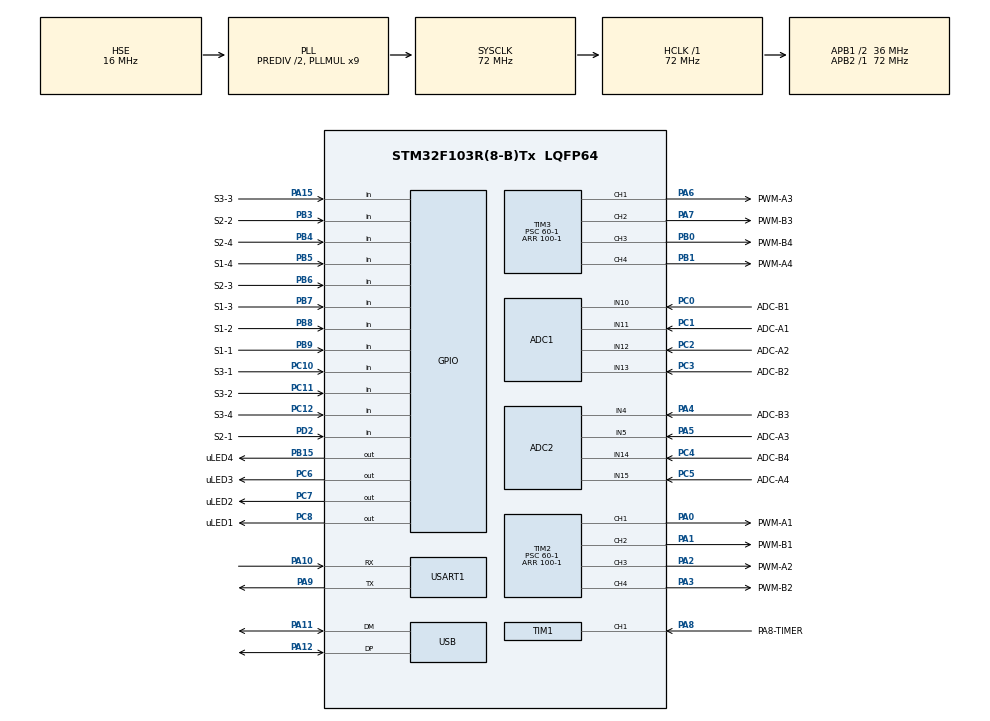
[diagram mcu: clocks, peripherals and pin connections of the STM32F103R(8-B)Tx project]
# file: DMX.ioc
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PC10.GPIO_PuPd=GPIO_PULLDOWN
PC12.Signal=GPIO_Input
PB14.GPIO_Label=PB14-TIMER
PC6.GPIO_Label=uLED3
PA6.GPIO_Label=PWM-A3
PB6.GPIO_Label=S2-3
TIM3.Channel-PWM\ Generation4\ CH4=TIM_CHANNEL_4
RCC.SYSCLKSource=RCC_SYSCLKSOURCE_PLLCLK
RCC.APB2TimFreq_Value=72000000
PB6.Signal=GPIO_Input
PC7.Signal=GPIO_Output
PC3.Signal=ADCx_IN13
SH.ADCx_IN15.0=ADC2_IN15,IN15
PC4.GPIO_Label=ADC-B4
PB1.GPIO_Label=PWM-A4
PA8.Signal=S_TIM1_CH1
TIM1.Channel-Input_Capture2_from_TI1=TIM_CHANNEL_2
VP_TIM1_VS_ClockSourceINT.Mode=Internal
Mcu.Package=LQFP64
PB9.Signal=GPIO_Input
TIM2.Prescaler=60-1
PB1.Signal=S_TIM3_CH4
SH.ADCx_IN14.0=ADC2_IN14,IN14
PA10.Signal=USART1_RX
PB9.GPIO_PuPd=GPIO_PULLDOWN
RCC.APB1TimFreq_Value=72000000
TIM1.Period=100-1
PC12.GPIO_PuPd=GPIO_PULLDOWN
PA4.GPIO_Label=ADC-B3
PB7.GPIO_PuPd=GPIO_PULLDOWN
PD2.GPIO_PuPd=GPIO_PULLDOWN
PB6.GPIO_PuPd=GPIO_PULLDOWN
PB8.GPIO_PuPd=GPIO_PULLDOWN
PC2.Signal=ADCx_IN12
PC6.Signal=GPIO_Output
RCC.USBPrescaler=RCC_USBCLKSOURCE_PLL_DIV1_5
PC0.Signal=ADCx_IN10
RCC.APB1CLKDivider=RCC_HCLK_DIV2
PA0-WKUP.GPIO_Label=PWM-A1
PA0-WKUP.Signal=S_TIM2_CH1_ETR
TIM3.Channel-PWM\ Generation3\ CH3=TIM_CHANNEL_3
PB8.GPIO_Label=S1-2
PA8.GPIO_Label=PA8-TIMER
PA9.Signal=USART1_TX
PB4.GPIO_PuPd=GPIO_PULLDOWN
PC6.PinState=GPIO_PIN_SET
PB14.Signal=TIM1_CH2N
PA5.Signal=ADCx_IN5
PB4.GPIO_Label=S2-4
PB15.GPIO_Label=uLED4
PA1.GPIO_Label=PWM-B1
SH.ADCx_IN4.0=ADC2_IN4,IN4
TIM2.Period=100-1
PA13.Mode=Serial_Wire
PC7.GPIO_Label=uLED2
ADC1.SamplingTime-1\#ChannelRegularConversion=ADC_SAMPLETIME_1CYCLE_5
PA4.Signal=ADCx_IN4
PB5.Signal=GPIO_Input
ADC1.master=1
PA5.GPIO_Label=ADC-A3
ADC2.NbrOfConversionFlag=1
TIM1.Channel-Input_Capture1_from_TI1=TIM_CHANNEL_1
PB5.GPIO_PuPd=GPIO_PULLDOWN
RCC.HSEDivPLL=RCC_HSE_PREDIV_DIV2
PC12.GPIO_Label=S3-4
USART1.VirtualMode=VM_ASYNC
ADC1.Rank-1\#ChannelRegularConversion=1
PA11.Signal=USB_DM
SH.S_TIM2_CH1_ETR.0=TIM2_CH1,PWM Generation1 CH1
ProjectManager.HeapSize=0x200
SH.ADCx_IN5.0=ADC2_IN5,IN5
NVIC.PriorityGroup=NVIC_PRIORITYGROUP_4
TIM3.Channel-PWM\ Generation2\ CH2=TIM_CHANNEL_2
PC3.GPIO_Label=ADC-B2
PD2.Signal=GPIO_Input
PB0.Signal=S_TIM3_CH3
PC1.Signal=ADCx_IN11
PD2.GPIO_Label=S2-1
Mcu.Family=STM32F1
USB_DEVICE.CLASS_NAME_FS=CDC
ADC2.Channel-0\#ChannelRegularConversion=ADC_CHANNEL_4
PC10.Signal=GPIO_Input
PC0.GPIO_Label=ADC-B1
PA11.Mode=Device
PB0.GPIO_Label=PWM-B4
TIM2.Channel-PWM\ Generation2\ CH2=TIM_CHANNEL_2
PB15.Signal=GPIO_Output
PB15.PinState=GPIO_PIN_SET
ProjectManager.StackSize=0x400
PC8.PinState=GPIO_PIN_SET
PD1-OSC_OUT.Signal=RCC_OSC_OUT
PA15.GPIO_Label=S3-3
PC11.GPIO_PuPd=GPIO_PULLDOWN
PA12.Signal=USB_DP
TIM1.Prescaler=60-1
RCC.HCLKFreq_Value=72000000
TIM3.Period=100-1
RCC.AHBFreq_Value=72000000
TIM3.Channel-PWM\ Generation1\ CH1=TIM_CHANNEL_1
RCC.HSE_VALUE=16000000
RCC.PLLMUL=RCC_PLL_MUL9
PB3.GPIO_PuPd=GPIO_PULLDOWN
PA14.Mode=Serial_Wire
TIM3.Prescaler=60-1
PC11.GPIO_Label=S3-2
PC7.PinState=GPIO_PIN_SET
PB7.Signal=GPIO_Input
TIM2.Channel-PWM\ Generation1\ CH1=TIM_CHANNEL_1
SH.S_TIM3_CH1.0=TIM3_CH1,PWM Generation1 CH1
PB7.GPIO_Label=S1-3
PA6.Signal=S_TIM3_CH1
PA2.GPIO_Label=PWM-A2
PC8.GPIO_ModeDefaultOutputPP=GPIO_MODE_OUTPUT_PP
PA15.Signal=GPIO_Input
ADC2.SamplingTime-0\#ChannelRegularConversion=ADC_SAMPLETIME_1CYCLE_5
PB5.GPIO_Label=S1-4
PC5.Signal=ADCx_IN15
ADC2.Rank-0\#ChannelRegularConversion=1
PC2.GPIO_Label=ADC-A2
VP_TIM3_VS_ClockSourceINT.Mode=Internal
PB4.Signal=GPIO_Input
PA3.Signal=S_TIM2_CH4
PB3.GPIO_Label=S2-2
TIM2.Channel-PWM\ Generation4\ CH4=TIM_CHANNEL_4
SH.ADCx_IN13.0=ADC1_IN13,IN13
PD1-OSC_OUT.Mode=HSE-External-Oscillator
PB9.GPIO_Label=S1-1
PC10.GPIO_Label=S3-1
PA10.Mode=Asynchronous
USB_DEVICE.VirtualModeFS=Cdc_FS
PC11.Signal=GPIO_Input
PC8.Signal=GPIO_Output
PC4.Signal=ADCx_IN14
PD0-OSC_IN.Signal=RCC_OSC_IN
SH.S_TIM3_CH3.0=TIM3_CH3,PWM Generation3 CH3
RCC.ADCPresc=RCC_ADCPCLK2_DIV6
PC8.GPIO_Label=uLED1
PA13.Signal=SYS_JTMS-SWDIO
SH.S_TIM2_CH2.0=TIM2_CH2,PWM Generation2 CH2
PA9.Mode=Asynchronous
SH.ADCx_IN12.0=ADC1_IN12,IN12
SH.S_TIM1_CH1.0=TIM1_CH1,Input_Capture1_from_TI1
SH.S_TIM1_CH1.1=TIM1_CH1,Input_Capture2_from_TI1
ProjectManager.TargetToolchain=STM32CubeIDE
VP_USB_DEVICE_VS_USB_DEVICE_CDC_FS.Mode=CDC_FS
ADC1.Channel-1\#ChannelRegularConversion=ADC_CHANNEL_10
RCC.USBFreq_Value=48000000
PA1.Signal=S_TIM2_CH2
PD0-OSC_IN.Mode=HSE-External-Oscillator
SH.S_TIM3_CH2.0=TIM3_CH2,PWM Generation2 CH2
board=custom
RCC.APB2Freq_Value=72000000
SH.ADCx_IN11.0=ADC1_IN11,IN11
VP_TIM2_VS_ClockSourceINT.Mode=Internal
SH.S_TIM2_CH3.0=TIM2_CH3,PWM Generation3 CH3
NVIC.USB_LP_CAN1_RX0_IRQn=true\:0\:0\:false\:false\:true\:false\:true
PC1.GPIO_Label=ADC-A1
TIM2.Channel-PWM\ Generation3\ CH3=TIM_CHANNEL_3
Mcu.Name=STM32F103R(8-B)Tx
PA2.Signal=S_TIM2_CH3
PB3.Signal=GPIO_Input
RCC.SYSCLKFreq_VALUE=72000000
PA7.GPIO_Label=PWM-B3
PA12.Mode=Device
PC5.GPIO_Label=ADC-A4
PA14.Signal=SYS_JTCK-SWCLK
SH.ADCx_IN10.0=ADC1_IN10,IN10
SH.S_TIM2_CH4.0=TIM2_CH4,PWM Generation4 CH4
ADC1.NbrOfConversionFlag=1
PA15.GPIO_PuPd=GPIO_PULLDOWN
PB8.Signal=GPIO_Input
RCC.APB1Freq_Value=36000000
USB_DEVICE.VirtualMode=Cdc
PA3.GPIO_Label=PWM-B2
SH.S_TIM3_CH4.0=TIM3_CH4,PWM Generation4 CH4
PA7.Signal=S_TIM3_CH2

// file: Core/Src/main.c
/* USER CODE BEGIN Header */
/**
  ******************************************************************************
  * @file           : main.c
  * @brief          : Main program body
  ******************************************************************************
  * @attention
  *
  * <h2><center>&copy; Copyright (c) 2021 STMicroelectronics.
  * All rights reserved.</center></h2>
  *
  * This software component is licensed by ST under BSD 3-Clause license,
  * the "License"; You may not use this file except in compliance with the
  * License. You may obtain a copy of the License at:
  *                        opensource.org/licenses/BSD-3-Clause
  *
  ******************************************************************************
  */
/* USER CODE END Header */
#include "main.h"
#include "usb_device.h"

/* USER CODE BEGIN Includes */

#include "core.h"

/* USER CODE END Includes */

ADC_HandleTypeDef hadc1;
ADC_HandleTypeDef hadc2;

TIM_HandleTypeDef htim1;
TIM_HandleTypeDef htim2;
TIM_HandleTypeDef htim3;

UART_HandleTypeDef huart1;

void SystemClock_Config(void);
static void MX_GPIO_Init(void);
static void MX_ADC1_Init(void);
static void MX_ADC2_Init(void);
static void MX_TIM1_Init(void);
static void MX_TIM2_Init(void);
static void MX_TIM3_Init(void);
static void MX_USART1_UART_Init(void);

/* USER CODE BEGIN 0 */

void TogglePortWithDelay(GPIO_TypeDef *GPIOx, uint16_t GPIO_Pin, uint8_t delay)
{
	HAL_GPIO_TogglePin(GPIOx, GPIO_Pin);
	HAL_Delay(delay);
}

/* USER CODE END 0 */

int main(void)
{

  /* MCU Configuration--------------------------------------------------------*/

  /* Reset of all peripherals, Initializes the Flash interface and the Systick. */
  HAL_Init();

  /* Configure the system clock */
  SystemClock_Config();

  /* Initialize all configured peripherals */
  MX_GPIO_Init();
  MX_ADC1_Init();
  MX_ADC2_Init();
  MX_TIM1_Init();
  MX_TIM2_Init();
  MX_TIM3_Init();
  MX_USART1_UART_Init();
  MX_USB_DEVICE_Init();
  /* USER CODE BEGIN 2 */

  if (!core_init())
    Error_Handler();

  /* USER CODE END 2 */

  /* Infinite loop */
  while (1)
  {

    /* USER CODE BEGIN 3 */

	  core_process();

  }
  /* USER CODE END 3 */
}

void SystemClock_Config(void)
{
  RCC_OscInitTypeDef RCC_OscInitStruct = {0};
  RCC_ClkInitTypeDef RCC_ClkInitStruct = {0};
  RCC_PeriphCLKInitTypeDef PeriphClkInit = {0};

  /** Initializes the RCC Oscillators according to the specified parameters
  * in the RCC_OscInitTypeDef structure.
  */
  RCC_OscInitStruct.OscillatorType = RCC_OSCILLATORTYPE_HSE;
  RCC_OscInitStruct.HSEState = RCC_HSE_ON;
  RCC_OscInitStruct.HSEPredivValue = RCC_HSE_PREDIV_DIV2;
  RCC_OscInitStruct.HSIState = RCC_HSI_ON;
  RCC_OscInitStruct.PLL.PLLState = RCC_PLL_ON;
  RCC_OscInitStruct.PLL.PLLSource = RCC_PLLSOURCE_HSE;
  RCC_OscInitStruct.PLL.PLLMUL = RCC_PLL_MUL9;
  if (HAL_RCC_OscConfig(&RCC_OscInitStruct) != HAL_OK)
  {
    Error_Handler();
  }
  /** Initializes the CPU, AHB and APB buses clocks
  */
  RCC_ClkInitStruct.ClockType = RCC_CLOCKTYPE_HCLK|RCC_CLOCKTYPE_SYSCLK
                              |RCC_CLOCKTYPE_PCLK1|RCC_CLOCKTYPE_PCLK2;
  RCC_ClkInitStruct.SYSCLKSource = RCC_SYSCLKSOURCE_PLLCLK;
  RCC_ClkInitStruct.AHBCLKDivider = RCC_SYSCLK_DIV1;
  RCC_ClkInitStruct.APB1CLKDivider = RCC_HCLK_DIV2;
  RCC_ClkInitStruct.APB2CLKDivider = RCC_HCLK_DIV1;

  if (HAL_RCC_ClockConfig(&RCC_ClkInitStruct, FLASH_LATENCY_2) != HAL_OK)
  {
    Error_Handler();
  }
  PeriphClkInit.PeriphClockSelection = RCC_PERIPHCLK_ADC|RCC_PERIPHCLK_USB;
  PeriphClkInit.AdcClockSelection = RCC_ADCPCLK2_DIV6;
  PeriphClkInit.UsbClockSelection = RCC_USBCLKSOURCE_PLL_DIV1_5;
  if (HAL_RCCEx_PeriphCLKConfig(&PeriphClkInit) != HAL_OK)
  {
    Error_Handler();
  }
}

static void MX_ADC1_Init(void)
{

  ADC_ChannelConfTypeDef sConfig = {0};

  /** Common config
  */
  hadc1.Instance = ADC1;
  hadc1.Init.ScanConvMode = ADC_SCAN_DISABLE;
  hadc1.Init.ContinuousConvMode = DISABLE;
  hadc1.Init.DiscontinuousConvMode = DISABLE;
  hadc1.Init.ExternalTrigConv = ADC_SOFTWARE_START;
  hadc1.Init.DataAlign = ADC_DATAALIGN_RIGHT;
  hadc1.Init.NbrOfConversion = 1;
  if (HAL_ADC_Init(&hadc1) != HAL_OK)
  {
    Error_Handler();
  }
  /** Configure Regular Channel
  */
  sConfig.Channel = ADC_CHANNEL_10;
  sConfig.Rank = ADC_REGULAR_RANK_1;
  sConfig.SamplingTime = ADC_SAMPLETIME_1CYCLE_5;
  if (HAL_ADC_ConfigChannel(&hadc1, &sConfig) != HAL_OK)
  {
    Error_Handler();
  }

}

static void MX_ADC2_Init(void)
{

  ADC_ChannelConfTypeDef sConfig = {0};

  /** Common config
  */
  hadc2.Instance = ADC2;
  hadc2.Init.ScanConvMode = ADC_SCAN_DISABLE;
  hadc2.Init.ContinuousConvMode = DISABLE;
  hadc2.Init.DiscontinuousConvMode = DISABLE;
  hadc2.Init.ExternalTrigConv = ADC_SOFTWARE_START;
  hadc2.Init.DataAlign = ADC_DATAALIGN_RIGHT;
  hadc2.Init.NbrOfConversion = 1;
  if (HAL_ADC_Init(&hadc2) != HAL_OK)
  {
    Error_Handler();
  }
  /** Configure Regular Channel
  */
  sConfig.Channel = ADC_CHANNEL_4;
  sConfig.Rank = ADC_REGULAR_RANK_1;
  sConfig.SamplingTime = ADC_SAMPLETIME_1CYCLE_5;
  if (HAL_ADC_ConfigChannel(&hadc2, &sConfig) != HAL_OK)
  {
    Error_Handler();
  }

}

static void MX_TIM1_Init(void)
{

  TIM_ClockConfigTypeDef sClockSourceConfig = {0};
  TIM_MasterConfigTypeDef sMasterConfig = {0};
  TIM_IC_InitTypeDef sConfigIC = {0};

  htim1.Instance = TIM1;
  htim1.Init.Prescaler = 60-1;
  htim1.Init.CounterMode = TIM_COUNTERMODE_UP;
  htim1.Init.Period = 100-1;
  htim1.Init.ClockDivision = TIM_CLOCKDIVISION_DIV1;
  htim1.Init.RepetitionCounter = 0;
  htim1.Init.AutoReloadPreload = TIM_AUTORELOAD_PRELOAD_DISABLE;
  if (HAL_TIM_Base_Init(&htim1) != HAL_OK)
  {
    Error_Handler();
  }
  sClockSourceConfig.ClockSource = TIM_CLOCKSOURCE_INTERNAL;
  if (HAL_TIM_ConfigClockSource(&htim1, &sClockSourceConfig) != HAL_OK)
  {
    Error_Handler();
  }
  if (HAL_TIM_IC_Init(&htim1) != HAL_OK)
  {
    Error_Handler();
  }
  sMasterConfig.MasterOutputTrigger = TIM_TRGO_RESET;
  sMasterConfig.MasterSlaveMode = TIM_MASTERSLAVEMODE_DISABLE;
  if (HAL_TIMEx_MasterConfigSynchronization(&htim1, &sMasterConfig) != HAL_OK)
  {
    Error_Handler();
  }
  sConfigIC.ICPolarity = TIM_INPUTCHANNELPOLARITY_RISING;
  sConfigIC.ICSelection = TIM_ICSELECTION_DIRECTTI;
  sConfigIC.ICPrescaler = TIM_ICPSC_DIV1;
  sConfigIC.ICFilter = 0;
  if (HAL_TIM_IC_ConfigChannel(&htim1, &sConfigIC, TIM_CHANNEL_1) != HAL_OK)
  {
    Error_Handler();
  }
  sConfigIC.ICSelection = TIM_ICSELECTION_INDIRECTTI;
  if (HAL_TIM_IC_ConfigChannel(&htim1, &sConfigIC, TIM_CHANNEL_2) != HAL_OK)
  {
    Error_Handler();
  }

}

static void MX_TIM2_Init(void)
{

  TIM_ClockConfigTypeDef sClockSourceConfig = {0};
  TIM_MasterConfigTypeDef sMasterConfig = {0};
  TIM_OC_InitTypeDef sConfigOC = {0};

  htim2.Instance = TIM2;
  htim2.Init.Prescaler = 60-1;
  htim2.Init.CounterMode = TIM_COUNTERMODE_UP;
  htim2.Init.Period = 100-1;
  htim2.Init.ClockDivision = TIM_CLOCKDIVISION_DIV1;
  htim2.Init.AutoReloadPreload = TIM_AUTORELOAD_PRELOAD_DISABLE;
  if (HAL_TIM_Base_Init(&htim2) != HAL_OK)
  {
    Error_Handler();
  }
  sClockSourceConfig.ClockSource = TIM_CLOCKSOURCE_INTERNAL;
  if (HAL_TIM_ConfigClockSource(&htim2, &sClockSourceConfig) != HAL_OK)
  {
    Error_Handler();
  }
  if (HAL_TIM_PWM_Init(&htim2) != HAL_OK)
  {
    Error_Handler();
  }
  sMasterConfig.MasterOutputTrigger = TIM_TRGO_RESET;
  sMasterConfig.MasterSlaveMode = TIM_MASTERSLAVEMODE_DISABLE;
  if (HAL_TIMEx_MasterConfigSynchronization(&htim2, &sMasterConfig) != HAL_OK)
  {
    Error_Handler();
  }
  sConfigOC.OCMode = TIM_OCMODE_PWM1;
  sConfigOC.Pulse = 0;
  sConfigOC.OCPolarity = TIM_OCPOLARITY_HIGH;
  sConfigOC.OCFastMode = TIM_OCFAST_DISABLE;
  if (HAL_TIM_PWM_ConfigChannel(&htim2, &sConfigOC, TIM_CHANNEL_1) != HAL_OK)
  {
    Error_Handler();
  }
  if (HAL_TIM_PWM_ConfigChannel(&htim2, &sConfigOC, TIM_CHANNEL_2) != HAL_OK)
  {
    Error_Handler();
  }
  if (HAL_TIM_PWM_ConfigChannel(&htim2, &sConfigOC, TIM_CHANNEL_3) != HAL_OK)
  {
    Error_Handler();
  }
  if (HAL_TIM_PWM_ConfigChannel(&htim2, &sConfigOC, TIM_CHANNEL_4) != HAL_OK)
  {
    Error_Handler();
  }
  HAL_TIM_MspPostInit(&htim2);

}

static void MX_TIM3_Init(void)
{

  TIM_ClockConfigTypeDef sClockSourceConfig = {0};
  TIM_MasterConfigTypeDef sMasterConfig = {0};
  TIM_OC_InitTypeDef sConfigOC = {0};

  htim3.Instance = TIM3;
  htim3.Init.Prescaler = 60-1;
  htim3.Init.CounterMode = TIM_COUNTERMODE_UP;
  htim3.Init.Period = 100-1;
  htim3.Init.ClockDivision = TIM_CLOCKDIVISION_DIV1;
  htim3.Init.AutoReloadPreload = TIM_AUTORELOAD_PRELOAD_DISABLE;
  if (HAL_TIM_Base_Init(&htim3) != HAL_OK)
  {
    Error_Handler();
  }
  sClockSourceConfig.ClockSource = TIM_CLOCKSOURCE_INTERNAL;
  if (HAL_TIM_ConfigClockSource(&htim3, &sClockSourceConfig) != HAL_OK)
  {
    Error_Handler();
  }
  if (HAL_TIM_PWM_Init(&htim3) != HAL_OK)
  {
    Error_Handler();
  }
  sMasterConfig.MasterOutputTrigger = TIM_TRGO_RESET;
  sMasterConfig.MasterSlaveMode = TIM_MASTERSLAVEMODE_DISABLE;
  if (HAL_TIMEx_MasterConfigSynchronization(&htim3, &sMasterConfig) != HAL_OK)
  {
    Error_Handler();
  }
  sConfigOC.OCMode = TIM_OCMODE_PWM1;
  sConfigOC.Pulse = 0;
  sConfigOC.OCPolarity = TIM_OCPOLARITY_HIGH;
  sConfigOC.OCFastMode = TIM_OCFAST_DISABLE;
  if (HAL_TIM_PWM_ConfigChannel(&htim3, &sConfigOC, TIM_CHANNEL_1) != HAL_OK)
  {
    Error_Handler();
  }
  if (HAL_TIM_PWM_ConfigChannel(&htim3, &sConfigOC, TIM_CHANNEL_2) != HAL_OK)
  {
    Error_Handler();
  }
  if (HAL_TIM_PWM_ConfigChannel(&htim3, &sConfigOC, TIM_CHANNEL_3) != HAL_OK)
  {
    Error_Handler();
  }
  if (HAL_TIM_PWM_ConfigChannel(&htim3, &sConfigOC, TIM_CHANNEL_4) != HAL_OK)
  {
    Error_Handler();
  }
  HAL_TIM_MspPostInit(&htim3);

}

static void MX_USART1_UART_Init(void)
{

  huart1.Instance = USART1;
  huart1.Init.BaudRate = 115200;
  huart1.Init.WordLength = UART_WORDLENGTH_8B;
  huart1.Init.StopBits = UART_STOPBITS_1;
  huart1.Init.Parity = UART_PARITY_NONE;
  huart1.Init.Mode = UART_MODE_TX_RX;
  huart1.Init.HwFlowCtl = UART_HWCONTROL_NONE;
  huart1.Init.OverSampling = UART_OVERSAMPLING_16;
  if (HAL_UART_Init(&huart1) != HAL_OK)
  {
    Error_Handler();
  }

}

static void MX_GPIO_Init(void)
{
  GPIO_InitTypeDef GPIO_InitStruct = {0};

  /* GPIO Ports Clock Enable */
  __HAL_RCC_GPIOD_CLK_ENABLE();
  __HAL_RCC_GPIOC_CLK_ENABLE();
  __HAL_RCC_GPIOA_CLK_ENABLE();
  __HAL_RCC_GPIOB_CLK_ENABLE();

  /*Configure GPIO pin Output Level */
  HAL_GPIO_WritePin(uLED4_GPIO_Port, uLED4_Pin, GPIO_PIN_SET);

  /*Configure GPIO pin Output Level */
  HAL_GPIO_WritePin(GPIOC, uLED3_Pin|uLED2_Pin|uLED1_Pin, GPIO_PIN_SET);

  /*Configure GPIO pin : uLED4_Pin */
  GPIO_InitStruct.Pin = uLED4_Pin;
  GPIO_InitStruct.Mode = GPIO_MODE_OUTPUT_PP;
  GPIO_InitStruct.Pull = GPIO_NOPULL;
  GPIO_InitStruct.Speed = GPIO_SPEED_FREQ_LOW;
  HAL_GPIO_Init(uLED4_GPIO_Port, &GPIO_InitStruct);

  /*Configure GPIO pins : uLED3_Pin uLED2_Pin uLED1_Pin */
  GPIO_InitStruct.Pin = uLED3_Pin|uLED2_Pin|uLED1_Pin;
  GPIO_InitStruct.Mode = GPIO_MODE_OUTPUT_PP;
  GPIO_InitStruct.Pull = GPIO_NOPULL;
  GPIO_InitStruct.Speed = GPIO_SPEED_FREQ_LOW;
  HAL_GPIO_Init(GPIOC, &GPIO_InitStruct);

  /*Configure GPIO pin : S3_3_Pin */
  GPIO_InitStruct.Pin = S3_3_Pin;
  GPIO_InitStruct.Mode = GPIO_MODE_INPUT;
  GPIO_InitStruct.Pull = GPIO_PULLDOWN;
  HAL_GPIO_Init(S3_3_GPIO_Port, &GPIO_InitStruct);

  /*Configure GPIO pins : S3_1_Pin S3_2_Pin S3_4_Pin */
  GPIO_InitStruct.Pin = S3_1_Pin|S3_2_Pin|S3_4_Pin;
  GPIO_InitStruct.Mode = GPIO_MODE_INPUT;
  GPIO_InitStruct.Pull = GPIO_PULLDOWN;
  HAL_GPIO_Init(GPIOC, &GPIO_InitStruct);

  /*Configure GPIO pin : S2_1_Pin */
  GPIO_InitStruct.Pin = S2_1_Pin;
  GPIO_InitStruct.Mode = GPIO_MODE_INPUT;
  GPIO_InitStruct.Pull = GPIO_PULLDOWN;
  HAL_GPIO_Init(S2_1_GPIO_Port, &GPIO_InitStruct);

  /*Configure GPIO pins : S2_2_Pin S2_4_Pin S1_4_Pin S2_3_Pin
                           S1_3_Pin S1_2_Pin S1_1_Pin */
  GPIO_InitStruct.Pin = S2_2_Pin|S2_4_Pin|S1_4_Pin|S2_3_Pin
                          |S1_3_Pin|S1_2_Pin|S1_1_Pin;
  GPIO_InitStruct.Mode = GPIO_MODE_INPUT;
  GPIO_InitStruct.Pull = GPIO_PULLDOWN;
  HAL_GPIO_Init(GPIOB, &GPIO_InitStruct);

}

void Error_Handler(void)
{
  __disable_irq();
  while (1)
  {
  }
}

/************************ (C) COPYRIGHT STMicroelectronics *****END OF FILE****/
